# iospear300 register map
Registers are 32-bit, access not given, no defined reset value unless marked. A register's access mark holds for its fields unless they carry their own. Addresses are absolute; registers are grouped by the start of their names; [hi:lo] are bit positions; {n}, {i} and the like mark numbered series; 'fields as' and 'values as' point back to an identical list.

## DMA
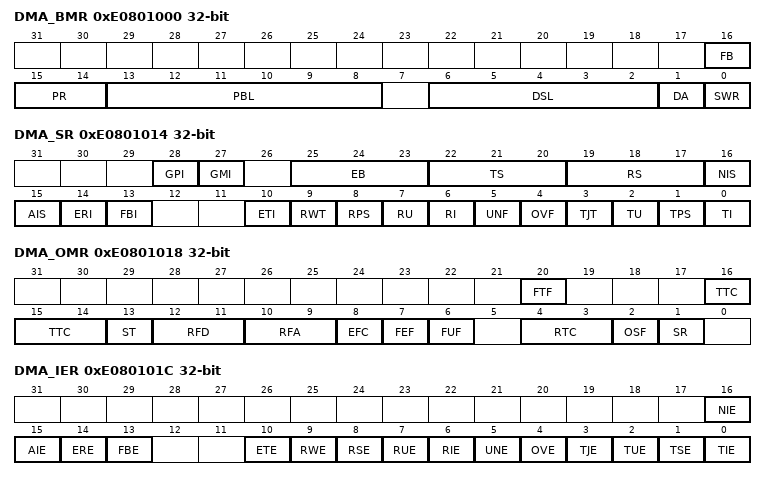
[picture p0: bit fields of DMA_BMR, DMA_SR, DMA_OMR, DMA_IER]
0xE0801000 DMA_BMR
  [16] FB, [15:14] PR, [13:8] PBL, [6:2] DSL, [1] DA, [0] SWR
0xE0801004 DMA_TPDR
0xE0801008 DMA_RPDR
0xE080100C DMA_RDLAR
0xE0801010 DMA_TDLAR
0xE0801014 DMA_SR
  [28] GPI, [27] GMI, [25:23] EB, [22:20] TS, [19:17] RS, [16] NIS, [15] AIS, [14] ERI, [13] FBI, [10] ETI, [9] RWT, [8] RPS, [7] RU, [6] RI, [5] UNF, [4] OVF, [3] TJT, [2] TU, [1] TPS, [0] TI
0xE0801018 DMA_OMR
  [20] FTF, [16:14] TTC, [13] ST, [12:11] RFD, [10:9] RFA, [8] EFC, [7] FEF, [6] FUF, [4:3] RTC, [2] OSF, [1] SR
0xE080101C DMA_IER
  [16] NIE, [15] AIE, [14] ERE, [13] FBE, [10] ETE, [9] RWE, [8] RSE, [7] RUE, [6] RIE, [5] UNE, [4] OVE, [3] TJE, [2] TUE, [1] TSE, [0] TIE
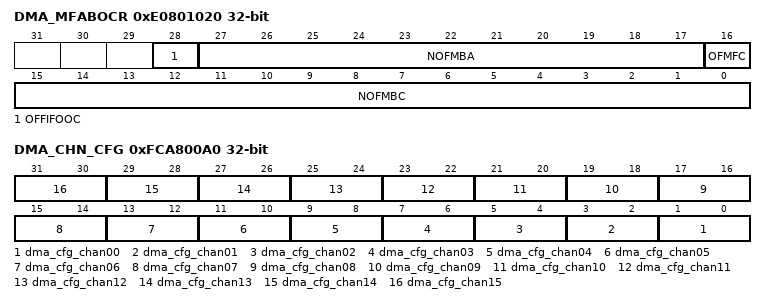
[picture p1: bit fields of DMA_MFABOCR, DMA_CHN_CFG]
0xE0801020 DMA_MFABOCR
  [28] OFFIFOOC, [27:17] NOFMBA, [16] OFMFC, [15:0] NOFMBC
0xE0801048 DMA_CHTDR
0xE080104C DMA_CHRDR
0xE0801050 DMA_CHTBAR
0xE0801054 DMA_CHRBAR
0xFCA800A0 DMA_CHN_CFG
  [2n+1:2n] dma_cfg_chan{n:02} (n=0..15)

## USB2
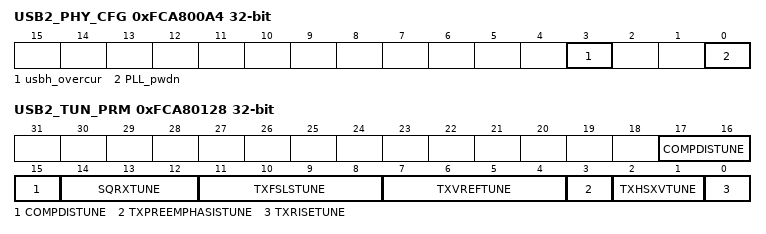
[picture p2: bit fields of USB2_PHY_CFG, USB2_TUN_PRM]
0xFCA800A4 USB2_PHY_CFG
  [3] usbh_overcur, [0] PLL_pwdn
0xFCA80128 USB2_TUN_PRM
  [17:15] COMPDISTUNE, [14:12] SQRXTUNE, [11:8] TXFSLSTUNE, [7:4] TXVREFTUNE, [3] TXPREEMPHASISTUNE, [2:1] TXHSXVTUNE, [0] TXRISETUNE

## PRC1
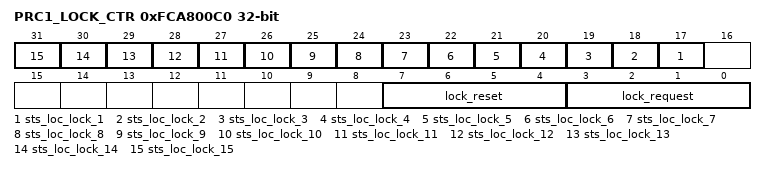
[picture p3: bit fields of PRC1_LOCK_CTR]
0xFCA800C0 PRC1_LOCK_CTR
  [n+16] sts_loc_lock_{n} (n=1..15), [7:4] lock_reset, [3:0] lock_request
0xFCA800D0 PRC1_IRQ_CTR
  [16] int2_req_prc1_1

## PRC2
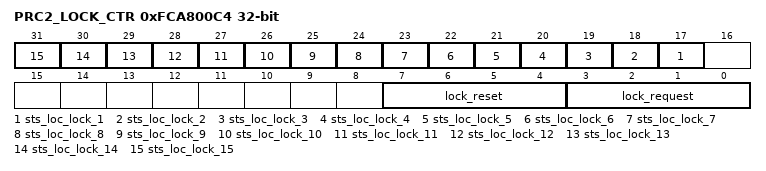
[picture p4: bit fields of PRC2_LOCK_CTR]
0xFCA800C4 PRC2_LOCK_CTR
  [n+16] sts_loc_lock_{n} (n=1..15), [7:4] lock_reset, [3:0] lock_request
0xFCA800D4 PRC2_IRQ_CTR
  [16] int2_req_prc1_1

## BIST1
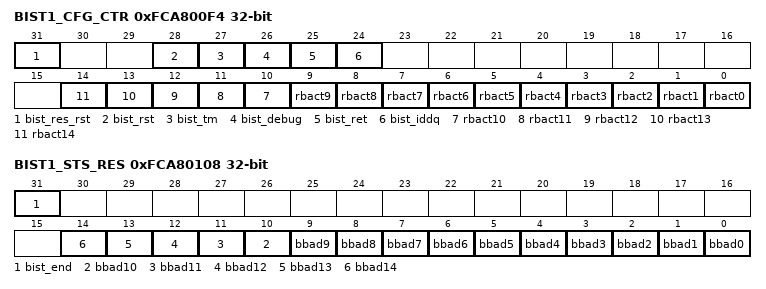
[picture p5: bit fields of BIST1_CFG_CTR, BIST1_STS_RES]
0xFCA800F4 BIST1_CFG_CTR
  [31] bist_res_rst, [28] bist_rst, [27] bist_tm, [26] bist_debug, [25] bist_ret, [24] bist_iddq, [n] rbact{n} (n=0..14)
0xFCA80108 BIST1_STS_RES
  [31] bist_end, [n] bbad{n} (n=0..14)

## BIST2
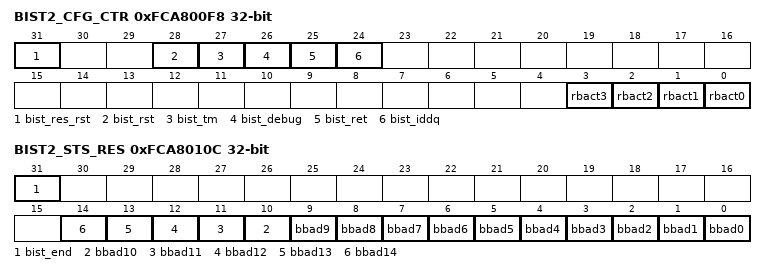
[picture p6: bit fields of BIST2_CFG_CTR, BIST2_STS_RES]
0xFCA800F8 BIST2_CFG_CTR
  [31] bist_res_rst, [28] bist_rst, [27] bist_tm, [26] bist_debug, [25] bist_ret, [24] bist_iddq, [n] rbact{n} (n=0..3)
0xFCA8010C BIST2_STS_RES
  [31] bist_end, [n] bbad{n} (n=0..14)

## BIST3
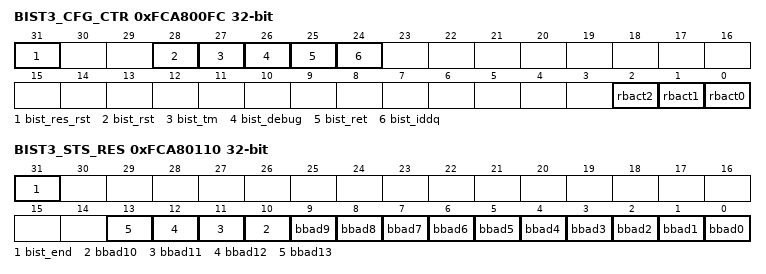
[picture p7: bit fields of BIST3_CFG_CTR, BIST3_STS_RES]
0xFCA800FC BIST3_CFG_CTR
  [31] bist_res_rst, [28] bist_rst, [27] bist_tm, [26] bist_debug, [25] bist_ret, [24] bist_iddq, [2] rbact2, [1] rbact1, [0] rbact0
0xFCA80110 BIST3_STS_RES
  [31] bist_end, [n] bbad{n} (n=0..13)

## BIST4
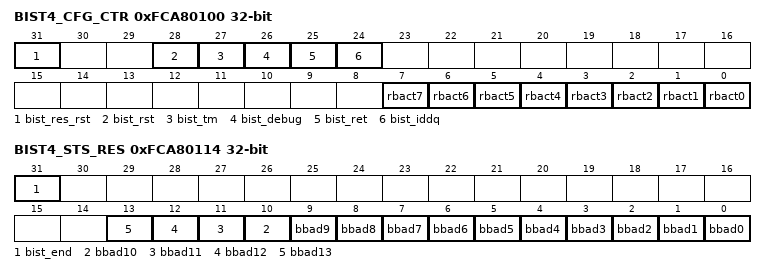
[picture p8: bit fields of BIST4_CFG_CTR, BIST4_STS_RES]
0xFCA80100 BIST4_CFG_CTR
  [31] bist_res_rst, [28] bist_rst, [27] bist_tm, [26] bist_debug, [25] bist_ret, [24] bist_iddq, [n] rbact{n} (n=0..7)
0xFCA80114 BIST4_STS_RES
  [31] bist_end, [n] bbad{n} (n=0..13)

## SMI
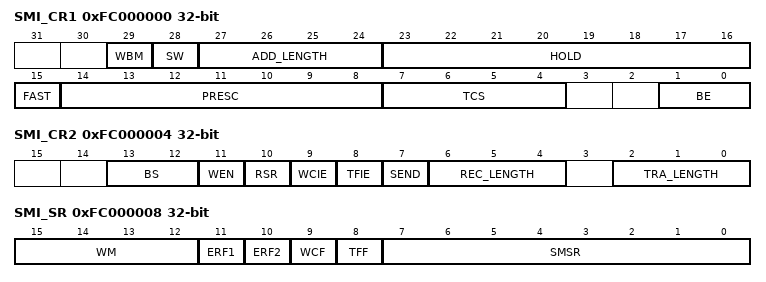
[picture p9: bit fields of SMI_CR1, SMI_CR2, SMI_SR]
0xFC000000 SMI_CR1
  [29] WBM, [28] SW, [27:24] ADD_LENGTH, [23:16] HOLD, [15] FAST, [14:8] PRESC, [7:4] TCS, [1:0] BE
0xFC000004 SMI_CR2
  [13:12] BS, [11] WEN, [10] RSR, [9] WCIE, [8] TFIE, [7] SEND, [6:4] REC_LENGTH, [2:0] TRA_LENGTH
0xFC000008 SMI_SR
  [15:12] WM, [11] ERF1, [10] ERF2, [9] WCF, [8] TFF, [7:0] SMSR
0xFC00000C SMI_TR
0xFC000010 SMI_RR

## TIMER0
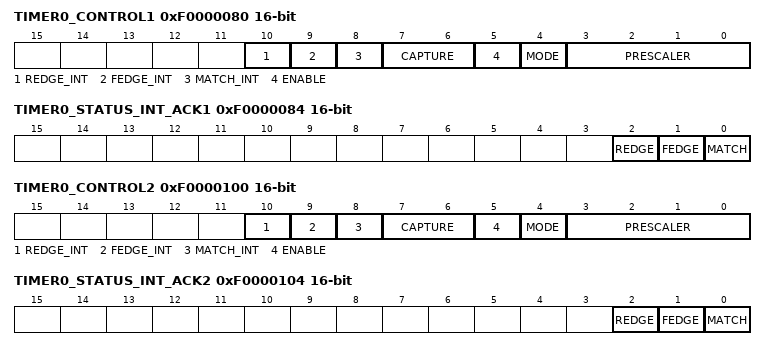
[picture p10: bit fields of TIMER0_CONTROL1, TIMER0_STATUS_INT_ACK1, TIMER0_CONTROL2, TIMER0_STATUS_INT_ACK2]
0xF0000080 TIMER0_CONTROL1 16-bit
  [10] REDGE_INT, [9] FEDGE_INT, [8] MATCH_INT, [7:6] CAPTURE, [5] ENABLE, [4] MODE, [3:0] PRESCALER
0xF0000084 TIMER0_STATUS_INT_ACK1 16-bit
  [2] REDGE, [1] FEDGE, [0] MATCH
0xF0000088 TIMER0_COMPARE1 16-bit
0xF000008C TIMER0_COUNT1 16-bit
0xF0000090 TIMER0_REDG_CAPT1 16-bit
0xF0000094 TIMER0_FEDG_CAPT1 16-bit
0xF0000100 TIMER0_CONTROL2 16-bit
  fields as TIMER0_CONTROL1
0xF0000104 TIMER0_STATUS_INT_ACK2 16-bit
  [2] REDGE, [1] FEDGE, [0] MATCH
0xF0000108 TIMER0_COMPARE2 16-bit
0xF000010C TIMER0_COUNT2 16-bit
0xF0000110 TIMER0_REDG_CAPT2 16-bit
0xF0000114 TIMER0_FEDG_CAPT2 16-bit

## TIMER1
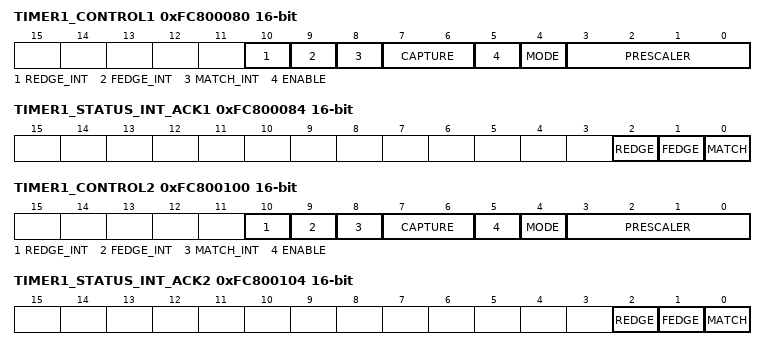
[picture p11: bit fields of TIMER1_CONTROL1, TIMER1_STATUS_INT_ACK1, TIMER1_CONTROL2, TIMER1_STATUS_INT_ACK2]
0xFC800080 TIMER1_CONTROL1 16-bit
  [10] REDGE_INT, [9] FEDGE_INT, [8] MATCH_INT, [7:6] CAPTURE, [5] ENABLE, [4] MODE, [3:0] PRESCALER
0xFC800084 TIMER1_STATUS_INT_ACK1 16-bit
  [2] REDGE, [1] FEDGE, [0] MATCH
0xFC800088 TIMER1_COMPARE1 16-bit
0xFC80008C TIMER1_COUNT1 16-bit
0xFC800090 TIMER1_REDG_CAPT1 16-bit
0xFC800094 TIMER1_FEDG_CAPT1 16-bit
0xFC800100 TIMER1_CONTROL2 16-bit
  fields as TIMER1_CONTROL1
0xFC800104 TIMER1_STATUS_INT_ACK2 16-bit
  [2] REDGE, [1] FEDGE, [0] MATCH
0xFC800108 TIMER1_COMPARE2 16-bit
0xFC80010C TIMER1_COUNT2 16-bit
0xFC800110 TIMER1_REDG_CAPT2 16-bit
0xFC800114 TIMER1_FEDG_CAPT2 16-bit
